# D1H.pdf register map
Vendor: Allwinner; Series: D1H.pdf; File version: 0.1
CPU: XuanTie C906 RISC-V CPU 0, little endian, MPU, FPU, double-precision FPU, 0 interrupt priority bits
Registers are 32-bit, read-write, reset 0x0 unless marked. A register's access mark holds for its fields unless they carry their own. Offsets are from the block's base; [hi:lo] are bit positions; {n}, {i} and the like mark numbered series; 'fields as' and 'values as' point back to an identical list.

## CSIC_PARSER0
Base 0x05801000
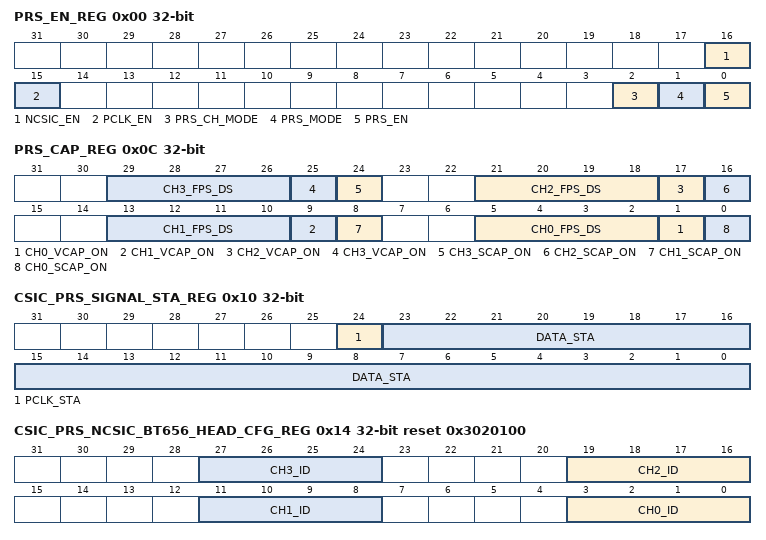
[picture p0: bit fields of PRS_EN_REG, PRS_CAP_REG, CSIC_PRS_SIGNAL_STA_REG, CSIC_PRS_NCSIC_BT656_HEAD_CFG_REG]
0x00 PRS_EN_REG — Parser Enable Register
  [16] NCSIC_EN — 0: Reset and disable the NCSIC module 1: Enable the NCSIC module
    0=Reset and disable the NCSIC module; 1=Enable the NCSIC module
  [15] PCLK_EN — 0: Gate pclk input 1: Enable pclk input
    0=Gate pclk input; 1=Enable pclk input
  [2] PRS_CH_MODE — 0: Parser output channel 0–3 corresponding from input channel 0–3 1: Parser output channel 0–3 all from input channel 0 (MIPI SEHDR)
    0=Parser output channel 0–3 corresponding from input channel 0–3; 1=Parser output channel 0–3 all from input channel 0 (MIPI SEHDR)
  [1] PRS_MODE — 0: Reserved 1: MCSI
    1=MCSI
  [0] PRS_EN — 0: Reset and disable the parser module 1: Enable the parser module
    0=Reset and disable the parser module; 1=Enable the parser module
0x0C PRS_CAP_REG — Parser Capture Register
  [8n+5:8n+2] CH{n}_FPS_DS (n=0..3) — Fps down sample 0: no down sample 1: 1/2 fps, only receives the first frame every 2 frames 2: 1/3 fps, only receives the first frame every 3 frames 3: 1/4 fps, only receives the first frame every 4 frames 4: 1/5 fps, only receives the first frame every 4 frames …… 15: 1/16 fps, only receives the first frame every 16 frames
    2=_1_slash_3 (1/3 fps, only receives the first frame every 3 frames); 3=_1_slash_4 (1/4 fps, only receives the first frame every 4 frames); 4=_1_slash_5 (1/5 fps, only receives the first frame every 4 frames ……); 15=_1_slash_16 (1/16 fps, only receives the first frame every 16 frames)
  [8n+1] CH{n}_VCAP_ON (n=0..3) — Video capture control: Capture the video image data stream on channel {n}. 0: Disable video capture If video capture is in progress, the CSI stops capturing image data at the end of the current frame, and all of the current frame data is written to output FIFO. 1: Enable video capture The CSI starts capturing image data at the start of the next frame.
    0=Disable video capture If video capture is in progress, the CSI stops capturing image data at the end of the current frame, and all of the current frame data is written to output FIFO; 1=Enable video capture The CSI starts capturing image data at the start of the next frame
  [24] CH3_SCAP_ON ro read-clears — Still capture control: Capture a single still image frame on channel 3. 0: Disable still capture 1: Enable still capture The CSI module starts capturing image data at the start of the next frame. The CSI module captures only one frame of image data. This bit is self cleared and always reads as a 0.
    0=Disable still capture; 1=Enable still capture The CSI module starts capturing image data at the start of the next frame. The CSI module captures only one frame of image data. This bit is self cleared and always reads as a 0.
  [16] CH2_SCAP_ON ro read-clears — Still capture control: Capture a single still image frame on channel 2. 0: Disable still capture 1: Enable still capture The CSI module starts capturing image data at the start of the next frame. The CSI module captures only one frame of image data. This bit is self cleared and always reads as a 0.
    values as CH3_SCAP_ON
  [8] CH1_SCAP_ON ro read-clears — Still capture control: Capture a single still image frame on channel 1. 0: Disable still capture 1: Enable still capture The CSI module starts capturing image data at the start of the next frame. The CSI module captures only one frame of image data. This bit is self cleared and always reads as a 0.
    values as CH3_SCAP_ON
  [0] CH0_SCAP_ON ro read-clears — Still capture control: Capture a single still image frame on channel 0. 0: Disable still capture. 1: Enable still capture The CSI module starts capturing image data at the start of the next frame. The CSI module captures only one frame of image data. This bit is self cleared and always reads as a 0.
    values as CH3_SCAP_ON
0x10 CSIC_PRS_SIGNAL_STA_REG — CSIC Parser Signal Status Register
  [24] PCLK_STA ro — Indicates the pclk status 0: low 1: high
    0=low; 1=high
  [23:0] DATA_STA ro — Indicates the Dn status (n=0–23), MSB for D23, LSB for D0 0: low 1: high
0x14 CSIC_PRS_NCSIC_BT656_HEAD_CFG_REG reset 0x3020100
  [8n+3:8n] CH{n}_ID (n=0..3) — The low 4-bit of BT656 header for channel {n} Only valid in BT656 multi-channel mode
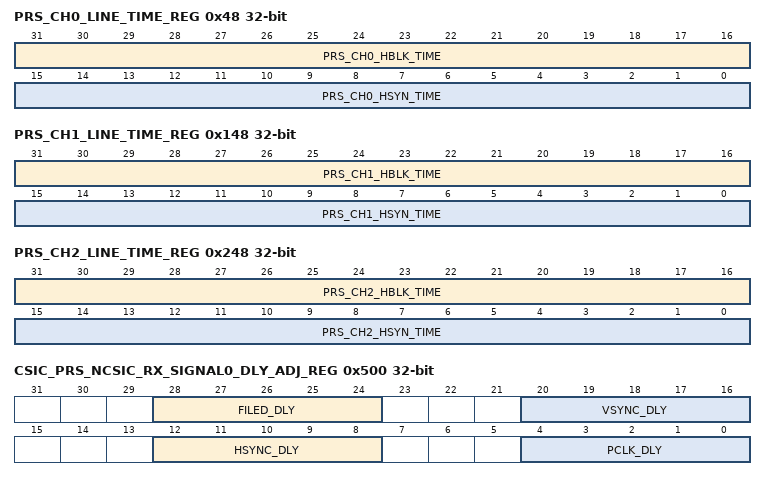
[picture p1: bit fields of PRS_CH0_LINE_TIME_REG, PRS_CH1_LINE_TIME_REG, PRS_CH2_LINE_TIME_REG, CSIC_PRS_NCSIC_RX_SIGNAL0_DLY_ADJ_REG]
0x48 PRS_CH0_LINE_TIME_REG — Parser Channel_0 Line Time Register
  [31:16] PRS_CH0_HBLK_TIME ro — Time of H Blanking when vsync is valid The unit is csi_top_clk cycle
  [15:0] PRS_CH0_HSYN_TIME ro — Time of H SYNC when vsync is valid The unit is csi_top_clk cycle
0x148 PRS_CH1_LINE_TIME_REG — Parser Channel_1 Line Time Register
  [31:16] PRS_CH1_HBLK_TIME ro — Time of H Blanking when vsync is valid The unit is csi_top_clk cycle.
  [15:0] PRS_CH1_HSYN_TIME ro — Time of H SYNC when vsync is valid The unit is csi_top_clk cycle.
0x248 PRS_CH2_LINE_TIME_REG — Parser Channel_2 Line Time Register
  [31:16] PRS_CH2_HBLK_TIME ro — Time of H Blanking when vsync is valid The unit is csi_top_clk cycle
  [15:0] PRS_CH2_HSYN_TIME ro — Time of H SYNC when vsync is valid The unit is csi_top_clk cycle
0x348 PRS_CH3_LINE_TIME_REG — Parser Channel_3 Line Time Register
  [15:0] PRS_CH3_HSYN_TIME ro — Time of H SYNC when vsync is valid The unit is csi_top_clk cycle
0x500 CSIC_PRS_NCSIC_RX_SIGNAL0_DLY_ADJ_REG
  [28:24] FILED_DLY — Filed_dly 32 Step for adjust, 1 step = 0.2 ns
  [20:16] VSYNC_DLY — Vsync_dly 32 Step for adjust, 1 step = 0.2 ns
  [12:8] HSYNC_DLY — Hsync_dly 32 Step for adjust, 1 step = 0.2 ns
  [4:0] PCLK_DLY — Pclk_dly 32 Step for adjust, 1 step = 0.2 ns
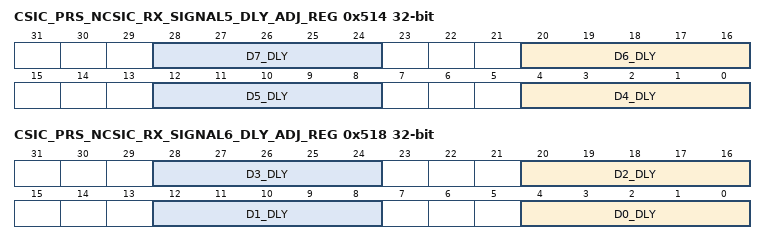
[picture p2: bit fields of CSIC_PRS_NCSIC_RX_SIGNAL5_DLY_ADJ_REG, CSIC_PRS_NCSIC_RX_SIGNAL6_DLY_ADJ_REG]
0x514 CSIC_PRS_NCSIC_RX_SIGNAL5_DLY_ADJ_REG
  [8n-28:8n-32] D{n}_DLY (n=4..7) — D{n}_dly 32 Step for adjust, 1 step = 0.2 ns
0x518 CSIC_PRS_NCSIC_RX_SIGNAL6_DLY_ADJ_REG
  [8n+4:8n] D{n}_DLY (n=0..3) — D{n}_dly 32 Step for adjust, 1 step = 0.2 ns
